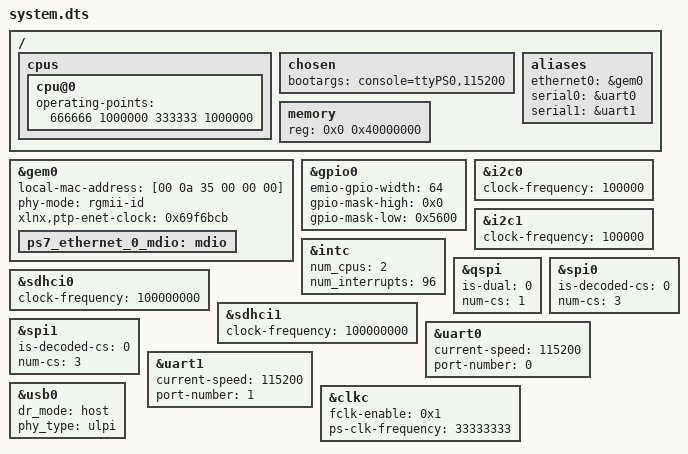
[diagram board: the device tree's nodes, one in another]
/*
 * CAUTION: This file is automatically generated by Xilinx.
 * Version: HSI 2014.4
 * Today is: Sat Apr 18 20:54:24 2015
*/


/dts-v1/;
/include/ "zynq-7000.dtsi"
/include/ "pl.dtsi"
/include/ "ethernet.dtsi"
/ {
	cpus {
		cpu@0 {
			operating-points = <666666 1000000 333333 1000000>;
		};
	};
	chosen {
		bootargs = "console=ttyPS0,115200";
	};
	aliases {
		ethernet0 = &gem0;
		serial0 = &uart0;
		serial1 = &uart1;
	};
	memory {
		device_type = "memory";
		reg = <0x0 0x40000000>;
	};
};
&gem0 {
	local-mac-address = [00 0a 35 00 00 00];
	phy-mode = "rgmii-id";
	status = "okay";
	xlnx,ptp-enet-clock = <0x69f6bcb>;
	ps7_ethernet_0_mdio: mdio {
		#address-cells = <1>;
		#size-cells = <0>;
	};
};
&gpio0 {
	emio-gpio-width = <64>;
	gpio-mask-high = <0x0>;
	gpio-mask-low = <0x5600>;
};
&i2c0 {
	clock-frequency = <100000>;
	status = "okay";
};
&i2c1 {
	clock-frequency = <100000>;
	status = "okay";
};
&intc {
	num_cpus = <2>;
	num_interrupts = <96>;
};
&qspi {
	is-dual = <0>;
	num-cs = <1>;
	status = "okay";
};
&sdhci0 {
	clock-frequency = <100000000>;
	status = "okay";
};
&sdhci1 {
	clock-frequency = <100000000>;
	status = "okay";
};
&spi0 {
	is-decoded-cs = <0>;
	num-cs = <3>;
	status = "okay";
};
&spi1 {
	is-decoded-cs = <0>;
	num-cs = <3>;
	status = "okay";
};
&uart0 {
	current-speed = <115200>;
	device_type = "serial";
	port-number = <0>;
	status = "okay";
};
&uart1 {
	current-speed = <115200>;
	device_type = "serial";
	port-number = <1>;
	status = "okay";
};
&usb0 {
	dr_mode = "host";
	phy_type = "ulpi";
	status = "okay";
};
&clkc {
	fclk-enable = <0x1>;
	ps-clk-frequency = <33333333>;
};
